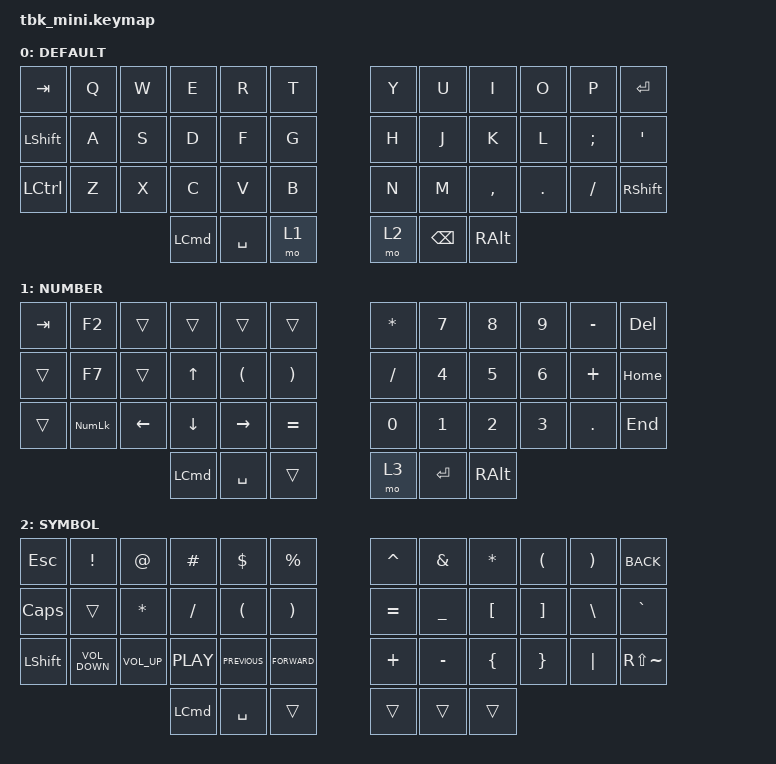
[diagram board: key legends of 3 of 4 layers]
/*
 * Copyright (c) 2020 The ZMK Contributors
 *
 * SPDX-License-Identifier: MIT
 */

#include <behaviors.dtsi>
#include <dt-bindings/zmk/bt.h>
#include <dt-bindings/zmk/keys.h>
#include <dt-bindings/zmk/rgb.h>

#define DEFAULT 0
#define NUMBER  1
#define SYMBOL  2
#define HOTKEY  3
#define SETTING 4

/ {
    keymap {
        compatible = "zmk,keymap";

        // -----------------------------------------------------------------------------------------
        // | TAB |  Q  |  W  |  E  |  R       |  T  |     |  Y  |  U        |  I  |  O  |  P  |   BKSP    |
        // | CTL |  A  |  S  |  D  |  F       |  G  |     |  H  |  J        |  K  |  L  |  ;  |     '     |
        // | ALT |  Z  |  X  |  C  |  V       |  B  |     |  N  |  M        |  ,  |  .  |  /  | SHFT/CLCK |
        //                    | GUI/~ | NUM/SPC | SHIFT |     | HTK/ENT | SYM/SPC  | GUI/BSPC |

        default_layer {
            label = "DEFAULT";
            bindings = <
&kp TAB           &kp Q  &kp W  &kp E             &kp R      &kp T    &kp Y  &kp U          &kp I          &kp O    &kp P     &kp ENTER
&kp LEFT_SHIFT    &kp A  &kp S  &kp D             &kp F      &kp G    &kp H  &kp J          &kp K          &kp L    &kp SEMI  &kp SQT
&kp LEFT_CONTROL  &kp Z  &kp X  &kp C             &kp V      &kp B    &kp N  &kp M          &kp COMMA      &kp DOT  &kp FSLH  &kp RIGHT_SHIFT
                                &kp LEFT_COMMAND  &kp SPACE  &mo 1    &mo 2  &kp BACKSPACE  &kp RIGHT_ALT
            >;
        };

        // -----------------------------------------------------------------------------------------
        // | ESC |  1  |  2  |  3  |  4  |  5  |   |  6  |  7  |  8  |  9  |  0  | DEL |
        // | CTL |  F1 |  F2 |  F3 | F4  |  F5 |   |  ←  |  ↓  |  ↑  |  →  |     |     |
        // | ALT |  F6 |  F7 |  F8 | F9  | F10 |   | F12 | F11 |     |     |     |     |
        //                   |     |     |     |   | SET |     |     |

        number_layer {
            label = "NUMBER";
            bindings = <
&kp TAB  &kp F2          &trans          &trans            &trans                &trans                   &kp STAR   &kp N7        &kp N8         &kp N9        &kp MINUS   &kp DEL
&trans   &kp F7          &trans          &kp UP_ARROW      &kp LEFT_PARENTHESIS  &kp RIGHT_PARENTHESIS    &kp SLASH  &kp NUMBER_4  &kp NUMBER_5   &kp NUMBER_6  &kp PLUS    &kp HOME
&trans   &kp KP_NUMLOCK  &kp LEFT_ARROW  &kp DOWN_ARROW    &kp RIGHT_ARROW       &kp EQUAL                &kp N0     &kp NUMBER_1  &kp NUMBER_2   &kp NUMBER_3  &kp PERIOD  &kp END
                                         &kp LEFT_COMMAND  &kp SPACE             &trans                   &mo 3      &kp ENTER     &kp RIGHT_ALT
            >;
        };

        // -----------------------------------------------------------------------------------------
        // | ESC  |  !  |  @  |  #  |  $  |  %  |     |  ^   |  &   |  *   |  (   |  )  | DEL |
        // |      |     |     |  "  |  :  |  ~  |     |  -   |  =   |  [   |  ]   |  \  |     |
        // |      |     |     |  '  |  ;  |  `  |     |  _   |  +   |  {   |  }   | "|" |     |
        //                    |     | SET |     |     |      |      |      |

        symbol_layer {
            label = "SYMBOL";
            bindings = <
&kp ESC         &kp EXCL           &kp AT           &kp HASH          &kp DLLR              &kp PRCNT                &kp CARET  &kp AMPS        &kp STAR  &kp LPAR  &kp RPAR  &kp K_BACK
&kp CAPSLOCK    &trans             &kp ASTERISK     &kp SLASH         &kp LEFT_PARENTHESIS  &kp RIGHT_PARENTHESIS    &kp EQUAL  &kp UNDERSCORE  &kp LBKT  &kp RBKT  &kp BSLH  &kp GRAVE
&kp LEFT_SHIFT  &kp C_VOLUME_DOWN  &kp C_VOLUME_UP  &kp C_PLAY        &kp C_PREVIOUS        &kp K_FORWARD            &kp PLUS   &kp MINUS       &kp LBRC  &kp RBRC  &kp PIPE  &kp RS(TILDE)
                                                    &kp LEFT_COMMAND  &kp SPACE             &trans                   &trans     &trans          &trans
            >;
        };

        // -----------------------------------------------------------------------------------------
        // |   |   |   |   |   |   |     |   |   |   |   |   |   |
        // |   |   |   |   |   |   |     |   |   |   |   |   |   |
        // |   |   |   |   |   |   |     |   |   |   |   |   |   |
        //             |     |     |     |     |     |

        hotkey_layer {
            label = "HOTKEY";
            bindings = <
&rgb_ug RGB_EFF  &rgb_ug RGB_HUI  &rgb_ug RGB_SAI  &rgb_ug RGB_BRI  &rgb_ug RGB_SPI  &rgb_ug RGB_TOG    &none   &none   &none  &none  &none  &none
&rgb_ug RGB_EFR  &rgb_ug RGB_HUD  &rgb_ug RGB_SAD  &rgb_ug RGB_BRD  &rgb_ug RGB_BRD  &none              &none   &none   &none  &none  &none  &none
&bt BT_CLR       &bt BT_SEL 0     &bt BT_SEL 1     &bt BT_SEL 2     &none            &none              &none   &kp F1  &none  &none  &none  &none
                                                   &trans           &trans           &trans             &trans  &trans
            >;
        };

        // -----------------------------------------------------------------------------------------
        // | RGB BRI+ | RGB SAT+ | RGB HUE+ | RGB ANI+ | | RGB TOG |     |  BT1  | BT2 | BT3 | BT4 | BT5 | BT CLR |
        // | RGB BRI- | RGB SAT- | RGB HUE- | RGB ANI- | |         |     |       |     |     |     |     |        |
        // |          |          |          |          | |         |     | RESET |     |     |     |     |        |
        //                                  |          | |         |     |       |     |     |
    };
};
